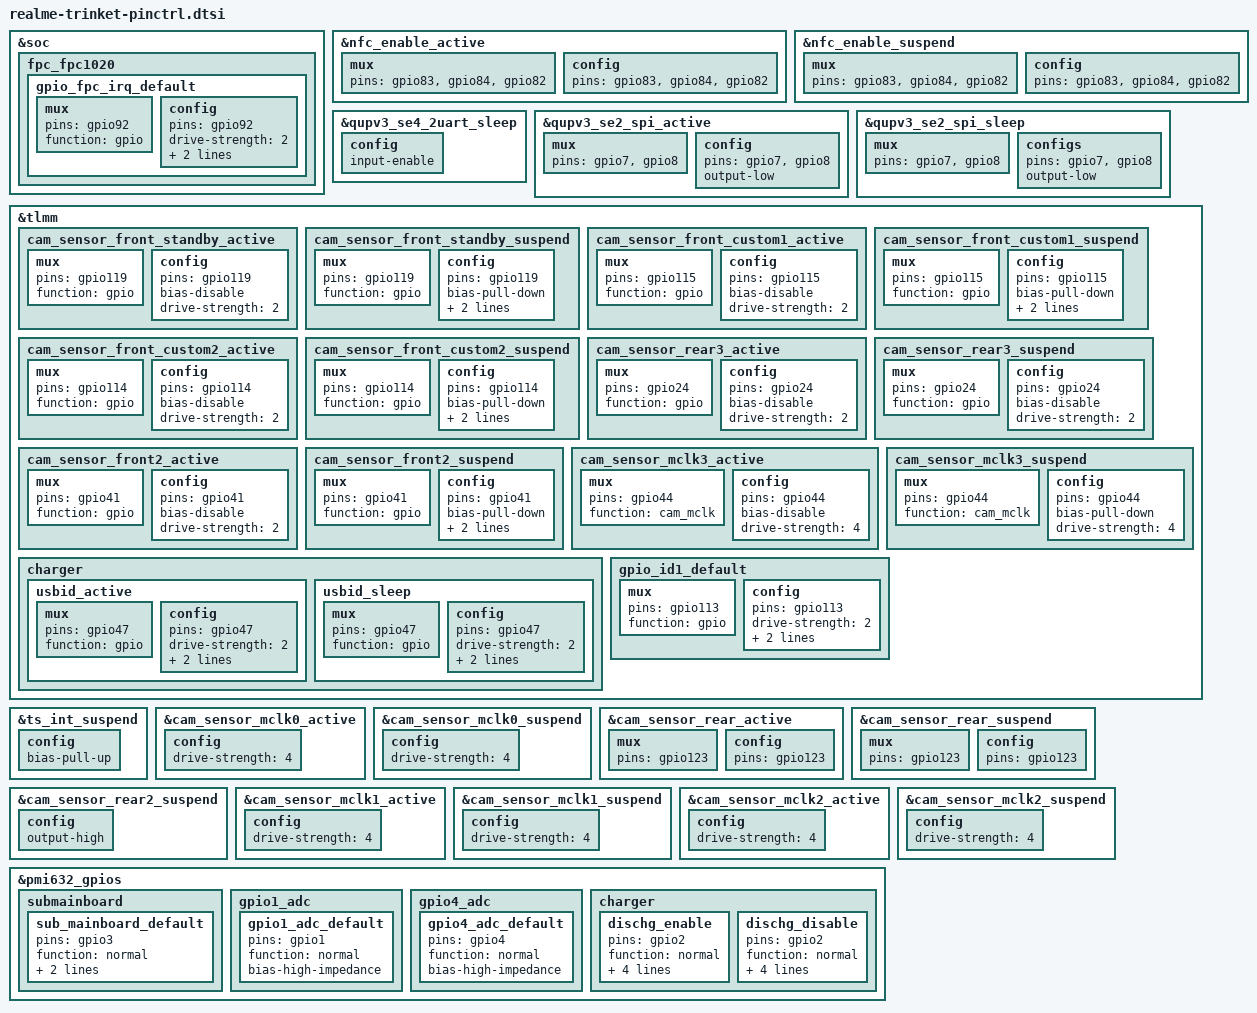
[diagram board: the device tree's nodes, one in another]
&soc {
    fpc_fpc1020{
        gpio_fpc_irq_default: gpio_fpc_irq_default {
            mux {
                pins = "gpio92";
                function = "gpio";
            };
            config {
                pins = "gpio92";
                drive-strength = <2>;
                bias-pull-up;
                input-enable;
            };
        };
    };

};

&nfc_enable_active {
    mux {
        /* 83: Enable 84: Firmware 82:eSE power*/
        pins = "gpio83", "gpio84", "gpio82";
    };

    config {
        pins = "gpio83", "gpio84", "gpio82";
    };
};

&nfc_enable_suspend {
    mux {
        /* 83: Enable 84: Firmware 82:eSE power*/
        pins = "gpio83", "gpio84", "gpio82";
    };

    config {
        pins = "gpio83", "gpio84", "gpio82";
    };
};

&qupv3_se4_2uart_sleep {
    config {
        input-enable;
    };
};

&qupv3_se2_spi_active {
    mux {
        pins = "gpio7", "gpio8";
    };

    config {
        pins = "gpio7", "gpio8";
        output-low;
    };
};

&qupv3_se2_spi_sleep {
    mux {
        pins = "gpio7", "gpio8";
    };

    configs {
        pins = "gpio7", "gpio8";
        output-low;
    };
};

&tlmm {
    /delete-node/ fpc_reset_int;
    /delete-node/ fpc_reset_high;
    /delete-node/ fpc_int_low;

    cam_sensor_front_standby_active: cam_sensor_front_standby_active {
        /* RESET  */
        mux {
            pins = "gpio119";
            function = "gpio";
        };

        config {
            pins = "gpio119";
            bias-disable; /* No PULL */
            drive-strength = <2>; /* 2 MA */
        };
    };

    cam_sensor_front_standby_suspend: cam_sensor_front_standby_suspend {
        /* RESET */
        mux {
            pins = "gpio119";
            function = "gpio";
        };

        config {
            pins = "gpio119";
            bias-pull-down; /* PULL DOWN */
            drive-strength = <2>; /* 2 MA */
            output-low;
        };
    };
    
    cam_sensor_front_custom1_active: cam_sensor_front_custom1_active {
        /* RESET  */
        mux {
            pins = "gpio115";
            function = "gpio";
        };

        config {
            pins = "gpio115";
            bias-disable; /* No PULL */
            drive-strength = <2>; /* 2 MA */
        };
    };

    cam_sensor_front_custom1_suspend: cam_sensor_front_custom1_suspend {
        /* RESET */
        mux {
            pins =  "gpio115";
            function = "gpio";
        };

        config {
            pins = "gpio115";
            bias-pull-down; /* PULL DOWN */
            drive-strength = <2>; /* 2 MA */
            output-low;
        };
    };
    
    cam_sensor_front_custom2_active: cam_sensor_front_custom2_active {
        /* RESET  */
        mux {
            pins = "gpio114";
            function = "gpio";
        };

        config {
            pins = "gpio114";
            bias-disable; /* No PULL */
            drive-strength = <2>; /* 2 MA */
        };
    };

    cam_sensor_front_custom2_suspend: cam_sensor_front_custom2_suspend {
        /* RESET */
        mux {
            pins =  "gpio114";
            function = "gpio";
        };

        config {
            pins = "gpio114";
            bias-pull-down; /* PULL DOWN */
            drive-strength = <2>; /* 2 MA */
            output-low;
        };
    };

    cam_sensor_rear3_active: cam_sensor_rear3_active {
        /* RESET */
        mux {
            pins = "gpio24";
            function = "gpio";
        };

        config {
            pins = "gpio24";
            bias-disable; /* No PULL */
            drive-strength = <2>; /* 2 MA */
        };
    };

    cam_sensor_rear3_suspend: cam_sensor_rear3_suspend {
        /* RESET */
        mux {
            pins = "gpio24";
            function = "gpio";
        };

        config {
            pins = "gpio24";
            bias-disable; /* No PULL */
            drive-strength = <2>; /* 2 MA */
        };
    };

    cam_sensor_front2_active: cam_sensor_front2_active {
        /*PWDN RESET*/
        mux {
            pins = "gpio41";
            function = "gpio";
        };

        config {
            pins = "gpio41";
            bias-disable; /* No PULL */
            drive-strength = <2>; /* 2 MA */
        };
    };

    cam_sensor_front2_suspend: cam_sensor_front2_suspend {
        /*PWDN RESET*/
        mux {
            pins = "gpio41";
            function = "gpio";
        };

        config {
            pins = "gpio41";
            bias-pull-down; /* PULL DOWN */
            drive-strength = <2>; /* 2 MA */
            output-low;
        };
    };

    cam_sensor_mclk3_active: cam_sensor_mclk3_active {
        /* MCLK3 */
        mux {
            pins = "gpio44";
            function = "cam_mclk";
        };

        config {
            pins = "gpio44";
            bias-disable; /* No PULL */
            drive-strength = <4>; /* 4 MA */
        };
    };

    cam_sensor_mclk3_suspend: cam_sensor_mclk3_suspend {
        /* MCLK2 */
        mux {
            pins = "gpio44";
            function = "cam_mclk";
        };

        config {
            pins = "gpio44";
            bias-pull-down; /* PULL DOWN */
            drive-strength = <4>; /* 4 MA */
        };
    };

    charger: charger {
        usbid_active: usbid_active {
            mux {
                pins = "gpio47";
                function = "gpio";
            };

            config {
                pins = "gpio47";
                drive-strength = <2>;
                input-enable;
                bias-pull-up;
            };
        };

        usbid_sleep: usbid_sleep {
            mux {
                pins = "gpio47";
                function = "gpio";
            };

            config {
                pins = "gpio47";
                drive-strength = <2>;
                input-enable;
                bias-pull-down;
            };
        };
    };

    gpio_id1_default: gpio_id1_default {
        mux {
            pins = "gpio113";
            function = "gpio";
        };
        config {
            pins = "gpio113";
            drive-strength = <2>;
            bias-pull-up;
            input-enable;
        };
    };
};

&ts_int_suspend {
    config {
        /delete-property/ bias-pull-down;
        bias-pull-up;
    };
};

&cam_sensor_mclk0_active {
    config {
        drive-strength = <4>; /* 4 MA */
    };
};

&cam_sensor_mclk0_suspend {
    config {
        drive-strength = <4>; /* 4 MA */
    };
};

&cam_sensor_rear_active {
    mux {
        pins = "gpio123";
    };

    config {
        pins = "gpio123";
    };
};

&cam_sensor_rear_suspend {
    mux {
        pins = "gpio123";
    };

    config {
        pins = "gpio123";
    };
};

&cam_sensor_rear2_suspend {
    config {
        /delete-property/ output-low;
        output-high;
    };
};

&cam_sensor_mclk1_active {
    config {
        drive-strength = <4>; /* 4 MA */
    };
};

&cam_sensor_mclk1_suspend {
    config {
        drive-strength = <4>; /* 4 MA */
    };
};

&cam_sensor_mclk2_active {
    config {
        drive-strength = <4>; /* 4 MA */
    };
};

&cam_sensor_mclk2_suspend {
    config {
        drive-strength = <4>; /* 4 MA */
    };
};

&pmi632_gpios {
	submainboard {
		sub_mainboard_default: sub_mainboard_default{
			pins = "gpio3";
			function = "normal"; /* normal */
			bias-high-impedance; /* disable GPIO for ADC*/
			bias-disable;
		};
	};

	gpio1_adc {
		gpio1_adc_default: gpio1_adc_default {
			pins = "gpio1"; /* GPIO 1 */
			function = "normal"; /* normal */
			bias-high-impedance; /* DISABLE GPIO1 for ADC*/
		};
	};

	gpio4_adc {
		gpio4_adc_default: gpio4_adc_default {
			pins = "gpio4"; /* GPIO 4 */
			function = "normal"; /* normal */
			bias-high-impedance; /* DISABLE GPIO4 for ADC*/
			};
	};

	charger {
		dischg_enable: dischg_enable{
			pins = "gpio2";
			function = "normal";
			qcom,drive-strength = <2>;
			power-source = <0>;
			bias-disable;
			output-high;
		};

		dischg_disable: dischg_disable{
			pins = "gpio2";
			function = "normal";
			qcom,drive-strength = <2>;
			power-source = <0>;
			bias-disable;
			output-low;
		};
	};
};
